# AT90PWM161 register map
Vendor: Atmel; File version: 1.0
CPU: other r0p0, little endian, no MPU, no FPU, 4 interrupt priority bits
Registers are 8-bit, read-write, reset 0x0 unless marked. A register's access mark holds for its fields unless they carry their own. Offsets are from the block's base; [hi:lo] are bit positions.

## FUSE — Fuses
Base 0x00000000
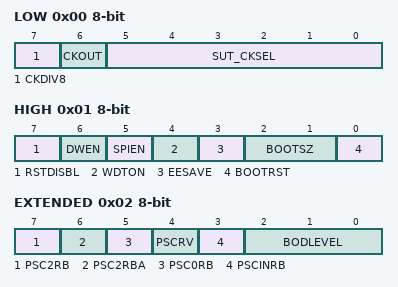
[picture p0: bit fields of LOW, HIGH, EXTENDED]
0x00 LOW
  [7] CKDIV8 — Divide clock by 8 internally
  [6] CKOUT — Clock output on PORTD1
  [5:0] SUT_CKSEL — Select Clock Source
    0=EXTCLK_PLLIN_RC_8MHZ_6CK_14CK_0MS (Ext. CK; PLLin: RC8; SUT: 6CK/14CK+0ms; [CKSEL=0000 SUT=00]); 1=PLLCLK_DIV4_PLLIN_RC_8MHZ_1KCK_14CK_0MS (PLL/4; PLLin: RC8; SUT: 1KCK/14CK+0 ms; [CKSEL=0001 SUT=00]); 2=RC_8MHZ_PLLIN_RC_8MHZ_6CK_14CK_0MS (RC8 MHz; PLLin: RC8; SUT: 6CK/14CK+0ms; [CKSEL=0010 SUT=00]); 3=WDOSC_128KHZ_1KCK_14CK_0MS (WD128 KHz; SUT: 1KCK/14CK+0 ms; [CKSEL=0011 SUT=00]); 4=PLLCLK_DIV4_PLLIN_XOSC_1KCK_14CK_0MS (PLL/4; PLLin: XOSC; SUT: 1KCK/14CK+0 ms; [CKSEL=0100 SUT=00]); 5=PLLCLK_DIV4_PLLIN_EXTCLK_16KCK_14CK_0MS (PLL/4; PLLin: Ext. CK; SUT: 16KCK/14CK+0 ms; [CKSEL=0101 SUT=00]); 6=RC_1MHZ_1KCK_14CK_0MS (RC 1 MHz; SUT: 1KCK/14CK+0 ms; [CKSEL=0110 SUT=00]); 8=XOSC_PLLIN_RC_8MHZ_258CK_14CK_4MS1 (XOSC.9-3MHz; PLLin: RC8; SUT: 258CK/14CK+4.1 ms; [CKSEL=1000 SUT=00]); 9=XOSC_PLLIN_RC_8MHZ_1KCK_14CK_65MS (XOSC.9-3MHz; PLLin: RC8; SUT: 1KCK/14CK+65 ms; [CKSEL=1001 SUT=00]); 10=XOSC_3MHZ_8MHZ_PLLIN_RC_8MHZ_258CK_14CK_4MS1 (XOSC3-8MHz; PLLin: RC8; SUT: 258CK/14CK+4.1 ms; [CKSEL=1010 SUT=00]); 11=XOSC_3MHZ_8MHZ_PLLIN_RC_8MHZ_1KCK_14CK_65MS (XOSC3-8MHz; PLLin: RC8; SUT: 1KCK/14CK+65 ms; [CKSEL=1011 SUT=00]); 12=XOSC_3MHZ_8MHZ_PLLIN_XOSC_258CK_14CK_4MS1 (XOSC3-8MHz; PLLin: XOSC; SUT: 258CK/14CK+4.1 ms; [CKSEL=1100 SUT=00]); 13=XOSC_3MHZ_8MHZ_PLLIN_XOSC_1KCK_14CK_65MS (XOSC3-8MHz; PLLin: XOSC; SUT: 1KCK/14CK+65 ms; [CKSEL=1101 SUT=00); 14=XOSC_8MHZ_16MHZ_PLLIN_RC_8MHZ_258CK_14CK_4MS1 (XOSC8-16MHz; PLLin: RC8; SUT: 258CK/14CK+4.1 ms; [CKSEL=1110 SUT=00]); 15=XOSC_8MHZ_16MHZ_PLLIN_RC_8MHZ_1KCK_14CK_65MS (XOSC8-16MHz; PLLin: RC8; SUT: 1KCK/14CK+65 ms; [CKSEL=1111 SUT=00]); 16=EXTCLK_PLLIN_RC_8MHZ_6CK_14CK_4MS1 (Ext. CK; PLLin: RC8 MHz; SUT:6 CK/14CK+4.1 ms; [CKSEL=0000 SUT=01]); 17=PLLCLK_DIV4_PLLIN_RC_8MHZ_1KCK_14CK_4MS (PLL/4; PLLin: RC8; SUT: 1KCK/14CK+4 ms; [CKSEL=0001 SUT=01]); 18=RC_8MHZ_PLLIN_RC_8MHZ_6CK_14CK_4MS1 (RC8 MHz; PLLin: RC8; SUT: 6CK/14CK+4.1 ms; [CKSEL=0010 SUT=01]); 19=WDOSC_128KHZ_1KCK_14CK_4MS1 (WD128 KHz; SUT: 1KCK/14CK+4.1 ms; [CKSEL=0011 SUT=01]); 20=PLLCLK_DIV4_PLLIN_XOSC_1KCK_14CK_4MS (PLL/4; PLLin: XOSC; SUT: 1KCK/14CK+4 ms; [CKSEL=0100 SUT=01]); 22=RC_1MHZ_1KCK_14CK_4MS1 (RC 1 MHz; SUT: 1KCK/14CK+4.1 ms; [CKSEL=0110 SUT=01]); 24=XOSC_PLLIN_RC_8MHZ_258CK_14CK_65MS (XOSC.9-3MHz; PLLin: RC8; SUT: 258CK/14CK+65 ms; [CKSEL=1000 SUT=01]); 25=XOSC_PLLIN_RC_8MHZ_16KCK_14CK_0MS (XOSC.9-3MHz; PLLin: RC8; SUT: 16KCK/14CK+0 ms; [CKSEL=1001 SUT=01]); 26=XOSC_3MHZ_8MHZ_PLLIN_RC_8MHZ_258CK_14CK_65MS (XOSC3-8MHz; PLLin: RC8; SUT: 258CK/14CK+65 ms; [CKSEL=1010 SUT=01]); 27=XOSC_3MHZ_8MHZ_PLLIN_RC_8MHZ_16KCK_14CK_0MS (XOSC3-8MHz; PLLin: RC8; SUT: 16KCK/14CK+0 ms; [CKSEL=1011 SUT=01]); 28=XOSC_3MHZ_8MHZ_PLLIN_XOSC_258CK_14CK_65MS (XOSC3-8MHz; PLLin: XOSC; SUT: 258CK/14CK+65 ms; [CKSEL=1100 SUT=01]); 29=XOSC_3MHZ_8MHZ_PLLIN_XOSC_16KCK_14CK_0MS (XOSC3-8MHz; PLLin: XOSC; SUT: 16KCK/14CK+0 ms; [CKSEL=1101 SUT=01]); 30=XOSC_8MHZ_16MHZ_PLLIN_RC_8MHZ_258CK_14CK_65MS (XOSC8-16MHz; PLLin: RC8; SUT: 258CK/14CK+65 ms; [CKSEL=1110 SUT=01]); 31=XOSC_8MHZ_16MHZ_PLLIN_RC_8MHZ_16KCK_14CK_0MS (XOSC8-16MHz; PLLin: RC8; SUT: 16KCK/14CK+0 ms; [CKSEL=1111 SUT=01]); 32=EXTCLK_PLLIN_RC_8MHZ_6CK_14CK_65MS (Ext. CK; PLLin: RC8 MHz; SUT:6 CK/14CK+65 ms; [CKSEL=0000 SUT=10]); 33=PLLCLK_DIV4_PLLIN_RC_8MHZ_1KCK_14CK_64MS (PLL/4; PLLin: RC8; SUT: 1KCK/14CK+64 ms; [CKSEL=0001 SUT=10]); 34=RC_8MHZ_PLLIN_RC_8MHZ_6CK_14CK_65MS (RC8 MHz; PLLin: RC8; SUT: 6CK/14CK+65 ms; [CKSEL=0010 SUT=10]); 35=WDOSC_128KHZ_1KCK_14CK_65MS (WD128 KHz; SUT: 1KCK/14CK+65 ms; [CKSEL=0011 SUT=10]); 36=PLLCLK_DIV4_PLLIN_XOSC_1KCK_14CK_64MS (PLL/4; PLLin: XOSC; SUT: 1KCK/14CK+64 ms; [CKSEL=0100 SUT=10]); 37=PLLCLK_DIV4_PLLIN_EXTCLK_16KCK_14CK_4MS (PLL/4; PLLin: Ext. CK; SUT: 16KCK/14CK+4 ms; [CKSEL=0101 SUT=10]); 38=RC_1MHZ_1KCK_14CK_65MS (RC 1 MHz; SUT: 1KCK/14CK+65 ms; [CKSEL=0110 SUT=10]); 40=XOSC_PLLIN_RC_8MHZ_1KCK_14CK_0MS (XOSC.9-3MHz; PLLin: RC8; SUT: 1KCK/14CK+0 ms; [CKSEL=1000 SUT=10]); 41=XOSC_PLLIN_RC_8MHZ_16KCK_14CK_4MS1 (XOSC.9-3MHz; PLLin: RC8; SUT: 16KCK/14CK+4.1 ms; [CKSEL=1001 SUT=10]); 42=XOSC_3MHZ_8MHZ_PLLIN_RC_8MHZ_1KCK_14CK_0MS (XOSC3-8MHz; PLLin: RC8; SUT: 1KCK/14CK+0 ms; [CKSEL=1010 SUT=10]); 43=XOSC_3MHZ_8MHZ_PLLIN_RC_8MHZ_16KCK_14CK_4MS1 (XOSC3-8MHz; PLLin: RC8; SUT: 16KCK/14CK+4.1 ms; [CKSEL=1011 SUT=10]); 44=XOSC_3MHZ_8MHZ_PLLIN_XOSC_1KCK_14CK_0MS (XOSC3-8MHz; PLLin: XOSC; SUT: 1KCK/14CK+0 ms; [CKSEL=1100 SUT=10]); 45=XOSC_3MHZ_8MHZ_PLLIN_XOSC_16KCK_14CK_4MS1 (XOSC3-8MHz; PLLin: XOSC; SUT: 16KCK/14CK+4.1 ms; [CKSEL=1101 SUT=10]); 46=XOSC_8MHZ_16MHZ_PLLIN_RC_8MHZ_1KCK_14CK_0MS (XOSC8-16MHz; PLLin: RC8; SUT: 1KCK/14CK+0 ms; [CKSEL=1110 SUT=10]); 47=XOSC_8MHZ_16MHZ_PLLIN_RC_8MHZ_16KCK_14CK_4MS1 (XOSC8-16MHz; PLLin: RC8; SUT: 16KCK/14CK+4.1 ms; [CKSEL=1111 SUT=10]); 51=WDOSC_128KHZ_16KCK_14CK_0MS (WD128 KHz; SUT: 16KCK/14CK+0 ms; [CKSEL=0011 SUT=11]); 52=PLLCLK_DIV4_PLLIN_XOSC_16KCK_14CK_0MS (PLL/4; PLLin: XOSC; SUT: 16KCK/14CK+0 ms; [CKSEL=0100 SUT=11]); 53=PLLCLK_DIV4_PLLIN_EXTCLK_16KCK_14CK_64MS (PLL/4; PLLin: Ext. CK; SUT: 16KCK/14CK+64 ms; [CKSEL=0101 SUT=11]); 56=XOSC_PLLIN_RC_8MHZ_1KCK_14CK_4MS1 (XOSC.9-3MHz; PLLin: RC8; SUT: 1KCK/14CK+4.1 ms; [CKSEL=1000 SUT=11]); 57=XOSC_PLLIN_RC_8MHZ_16KCK_14CK_65MS (XOSC.9-3MHz; PLLin: RC8; SUT: 16KCK/14CK+65 ms; [CKSEL=1001 SUT=11]); 58=XOSC_3MHZ_8MHZ_PLLIN_RC_8MHZ_1KCK_14CK_4MS1 (XOSC3-8MHz; PLLin: RC8; SUT: 1KCK/14CK+4.1 ms; [CKSEL=1010 SUT=11]); 59=XOSC_3MHZ_8MHZ_PLLIN_RC_8MHZ_16KCK_14CK_65MS (XOSC3-8MHz; PLLin: RC8; SUT: 16KCK/14CK+65 ms; [CKSEL=1011 SUT=11]); 60=XOSC_3MHZ_8MHZ_PLLIN_XOSC_1KCK_14CK_4MS1 (XOSC3-8MHz; PLLin: XOSC; SUT: 1KCK/14CK+4.1 ms; [CKSEL=1100 SUT=11]); 61=XOSC_3MHZ_8MHZ_PLLIN_XOSC_16KCK_14CK_65MS (XOSC3-8MHz; PLLin: XOSC; SUT: 16KCK/14CK+65 ms; [CKSEL=1101 SUT=11]); 62=XOSC_8MHZ_16MHZ_PLLIN_RC_8MHZ_1KCK_14CK_4MS1 (XOSC8-16MHz; PLLin: RC8; SUT: 1KCK/14CK+4.1 ms; [CKSEL=1110 SUT=11]); 63=XOSC_8MHZ_16MHZ_PLLIN_RC_8MHZ_16KCK_14CK_65MS (XOSC8-16MHz; PLLin: RC8; SUT: 16KCK/14CK+65 ms; [CKSEL=1111 SUT=11])
0x01 HIGH
  [7] RSTDISBL — Reset Disabled (Enable PE0 as I/O pin)
  [6] DWEN — Debug Wire enable
  [5] SPIEN — Serial program downloading (SPI) enabled
  [4] WDTON — Watch-dog Timer always on
  [3] EESAVE — Preserve EEPROM through the Chip Erase cycle
  [2:1] BOOTSZ — Select Boot Size
    0=1024W_0C00 (Boot Flash size=1024 words Boot address=$0C00); 1=512W_0E00 (Boot Flash size=512 words Boot address=$0E00); 2=256W_0F00 (Boot Flash size=256 words Boot address=$0F00); 3=128W_0F80 (Boot Flash size=128 words Boot address=$0F80)
  [0] BOOTRST — Select Reset Vector
0x02 EXTENDED
  [7] PSC2RB — PSC2 Reset Behavior
  [6] PSC2RBA — PSC2 Reset Behavior for 22 and 23
  [5] PSC0RB — PSC0 Reset Behavior
  [4] PSCRV — PSC Reset Value
  [3] PSCINRB — PSC2 and PSC0 input Reset Behavior
  [2:0] BODLEVEL — Brown-out Detector Trigger Level
    0=2V0 (Brown-out detection at VCC=2.0 V); 1=1V9 (Brown-out detection at VCC=1.9 V); 2=2V2 (Brown-out detection at VCC=2.2 V); 3=2V3 (Brown-out detection at VCC=2.3 V); 4=4V3 (Brown-out detection at VCC=4.3 V); 5=2V7 (Brown-out detection at VCC=2.7 V); 6=1V8 (Brown-out detection at VCC=1.8 V); 7=DISABLED (Brown-out detection disabled)
